# ATtiny840 device description
Architecture: AVR8; Family: tinyAVR
Programming and debug interfaces: ISP, HVSP, debugWIRE
Registers are 8-bit, access not given, no defined reset value unless marked. A register's access mark holds for its fields unless they carry their own. Offsets are from the block's base; lines under a group give offsets from that group; [hi:lo] are bit positions; {n}, {i} and the like mark numbered series; 'fields as' and 'values as' point back to an identical list; <NAME> marks a mode.

## Ordering variants
ATtiny840-XBT, ATtiny840-XNR: up to 16 MHz, -40 to 105 C, 1.8 to 5.5 V

## Memory
prog space: start 0x0000 size 0x2000, little endian
  0x0000 FLASH size 0x2000 flash, rw, executable, page 0x40
  0x1f00 BOOT_SECTION_1 size 0x0100 flash, rw, executable, page 0x40
  0x1e00 BOOT_SECTION_2 size 0x0200 flash, rw, executable, page 0x40
  0x1c00 BOOT_SECTION_3 size 0x0400 flash, rw, executable, page 0x40
  0x1800 BOOT_SECTION_4 size 0x0800 flash, rw, executable, page 0x40
signatures space: start 0 size 3, little endian
  0 SIGNATURES size 3 signatures, ro
fuses space: start 0 size 0x0003, little endian
  0 FUSES size 0x0003 fuses, rw
lockbits space: start 0 size 0x0001, little endian
  0 LOCKBITS size 0x0001 lockbits, rw
data space: start 0x0000 size 0x0500, little endian
  0x0000 REGISTERS size 0x0020 regs
  0x0020 MAPPED_IO size 0x00e0 io
  0x0100 IRAM size 0x0400 ram
eeprom space: start 0x0000 size 0x0200, little endian
  0x0000 EEPROM size 0x0200 eeprom, rw, page 0x04
io space: start 0x00 size 0x40, little endian
osccal space: start 0 size 1, little endian
  0 OSCCAL size 1 osccal, ro

## Peripheral instances (address, pins/pin function, parameters)
USART1 at 0x00 — USART
TC1 at 0x00 — Timer/Counter, 16-bit
TC2 at 0x00 — Timer/Counter, 8-bit Async
AC at 0x00 — Analog Comparator
PORTB at 0x00 — I/O Port
PORTC at 0x00 — I/O Port
PORTD at 0x00 — I/O Port
TC0 at 0x00 — Timer/Counter, 8-bit
EXINT at 0x00 — External Interrupts
SPI at 0x00 — Serial Peripheral Interface
WDT at 0x00 — Watchdog Timer
EEPROM at 0x00
CPU at 0x00 — CPU Registers
DEVICEID at 0x0
FUSE at 0 in fuses — Fuses
LOCKBIT at 0 in lockbits — Lockbits

## Interrupts
0 RESET — External Pin, Power-on Reset, Brown-out Reset and Watchdog Reset
1 INT0 — External Interrupt Request 0
3 PCINT0 — Pin Change Interrupt Request 0
4 PCINT1 — Pin Change Interrupt Request 0
5 PCINT2 — Pin Change Interrupt Request 1
6 WDT — Watchdog Time-out Interrupt
7 TIMER2_COMPA — Timer/Counter2 Compare Match A
8 TIMER2_COMPB — Timer/Counter2 Compare Match A
9 TIMER2_OVF — Timer/Counter2 Overflow
10 TIMER1_CAPT — Timer/Counter1 Capture Event
11 TIMER1_COMPA — Timer/Counter1 Compare Match A
12 TIMER1_COMPB — Timer/Counter1 Compare Match B
13 TIMER1_OVF — Timer/Counter1 Overflow
14 TIMER0_COMPA — TimerCounter0 Compare Match A
15 TIMER0_COMPB — TimerCounter0 Compare Match B
16 TIMER0_OVF — Timer/Couner0 Overflow
17 SPI_STC — SPI Serial Transfer Complete
21 CLI — Custom Logic Interrupt
22 EE_READY — EEPROM Ready
23 ANALOG_COMP — Analog Comparator
25 SPM_Ready — Store Program Memory Read
28 USART_RX — USART Rx Complete
29 USART_UDRE — USART, Data Register Empty
30 USART_TX — USART Tx Complete
31 USART_START — USART Start Edge Interrupt
32 TIMER3_CAPT — Timer/Counter3 Capture Event
33 TIMER3_COMPA — Timer/Counter3 Compare Match A
34 TIMER3_COMPB — Timer/Counter3 Compare Match B
35 TIMER3_OVF — Timer/Counter3 Overflow
37 PTC_EOC — PTC End of conversion
38 PTC_WCOMP — PTC Window comparator mode

## Properties
SIGNATURES: JTAGID=0x93C3, SIGNATURE0=0x1e, SIGNATURE1=0x93, SIGNATURE2=0xC3
OCD: OCD_REVISION=1, OCD_DATAREG=0x31, PROGBASE=0x0000

## FUSE — Fuses
Instances: FUSE 0 in fuses
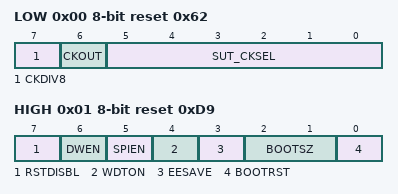
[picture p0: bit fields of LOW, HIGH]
0x00 LOW reset 0x62
  [7] CKDIV8 — Divide clock by 8 internally
  [6] CKOUT — Clock output on Port
  [5:0] SUT_CKSEL — Select Clock Source
    0=EXTCLK_6CK_14CK_0MS (Ext. Clock; Start-up time PWRDWN/RESET: 6 CK/14 CK + 0 ms); 16=EXTCLK_6CK_14CK_4MS1 (Ext. Clock; Start-up time PWRDWN/RESET: 6 CK/14 CK + 4.1 ms); 32=EXTCLK_6CK_14CK_65MS (Ext. Clock; Start-up time PWRDWN/RESET: 6 CK/14 CK + 65 ms); 2=INTRCOSC_8MHZ_6CK_14CK_0MS (Int. RC Osc. 8 MHz; Start-up time PWRDWN/RESET: 6 CK/14 CK + 0 ms); 18=INTRCOSC_8MHZ_6CK_14CK_4MS1 (Int. RC Osc. 8 MHz; Start-up time PWRDWN/RESET: 6 CK/14 CK + 4.1 ms); 34=INTRCOSC_8MHZ_6CK_14CK_65MS (Int. RC Osc. 8 MHz; Start-up time PWRDWN/RESET: 6 CK/14 CK + 65 ms); 3=INTRCOSC_128KHZ_6CK_14CK_0MS (Int. RC Osc. 128kHz; Start-up time PWRDWN/RESET: 6 CK/14 CK + 0 ms); 19=INTRCOSC_128KHZ_6CK_14CK_4MS1 (Int. RC Osc. 128kHz; Start-up time PWRDWN/RESET: 6 CK/14 CK + 4.1 ms); 35=INTRCOSC_128KHZ_6CK_14CK_65MS (Int. RC Osc. 128kHz; Start-up time PWRDWN/RESET: 6 CK/14 CK + 65 ms)
0x01 HIGH reset 0xD9
  [7] RSTDISBL — Reset Disabled (Enable PC6 as i/o pin)
  [6] DWEN — Debug Wire enable
  [5] SPIEN — Serial program downloading (SPI) enabled
  [4] WDTON — Watch-dog Timer always on
  [3] EESAVE — Preserve EEPROM through the Chip Erase cycle
  [2:1] BOOTSZ — Select boot size
    3=128W_1F80 (Boot Flash size=128 words start address=$1F80); 2=256W_1F00 (Boot Flash size=256 words start address=$1F00); 1=512W_1E00 (Boot Flash size=512 words start address=$1E00); 0=1024W_1C00 (Boot Flash size=1024 words start address=$1C00)
  [0] BOOTRST — Boot Reset vector Enabled
0x02 EXTENDED reset 0xFF
  [2:0] BODLEVEL — Brown-out Detector trigger level
    4=4V3 (Brown-out detection at VCC=4.3 V); 5=2V7 (Brown-out detection at VCC=2.7 V); 6=1V8 (Brown-out detection at VCC=1.8 V); 7=DISABLED (Brown-out detection disabled)
